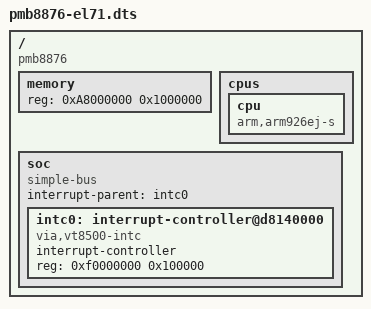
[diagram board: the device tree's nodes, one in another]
/*
 * wm8505.dtsi - Device tree file for Wondermedia WM8505 SoC
 *
 * Copyright (C) 2012 Tony Prisk <linux@prisktech.co.nz>
 *
 * Licensed under GPLv2 or later
 */

/dts-v1/;

/include/ "skeleton.dtsi"

/ {
	compatible = "pmb8876";
	
	memory { device_type = "memory"; reg = <0xA8000000 0x1000000>; };

	cpus {
		#address-cells = <0>;
		#size-cells = <0>;

		cpu {
			device_type = "cpu";
			compatible = "arm,arm926ej-s";
		};
	};

	soc {
		#address-cells = <1>;
		#size-cells = <1>;
		compatible = "simple-bus";
		ranges;
		interrupt-parent = <&intc0>;

		intc0: interrupt-controller@d8140000 {
			compatible = "via,vt8500-intc";
			interrupt-controller;
			reg = <0xf0000000 0x100000>;
			#interrupt-cells = <1>;
		};
    };
};
